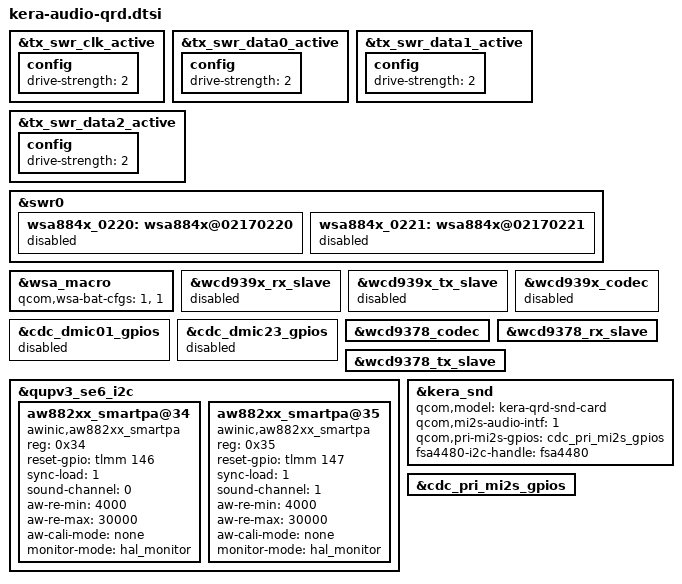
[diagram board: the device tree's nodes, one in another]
// SPDX-License-Identifier: BSD-3-Clause
/*
 * Copyright (c) 2023-2025 Qualcomm Innovation Center, Inc. All rights reserved.
 */
#include "kera-audio-overlay.dtsi"
#include "../kera-audio-lpass-reg.dtsi"

&tx_swr_clk_active {
	config {
		drive-strength = <2>;
	};
};

&tx_swr_data0_active {
	config {
		drive-strength = <2>;
	};
};

&tx_swr_data1_active {
	config {
		drive-strength = <2>;
	};
};

&tx_swr_data2_active {
	config {
		drive-strength = <2>;
	};
};

&swr0 {
	wsa884x_0220: wsa884x@02170220 {
		status = "disabled";
	};

	wsa884x_0221: wsa884x@02170221 {
		status = "disabled";
	};
};

&wsa_macro {
	qcom,wsa-bat-cfgs = <1>, <1>;
};

&wcd939x_rx_slave {
	status = "disabled";
};

&wcd939x_tx_slave {
	status = "disabled";
};

&wcd939x_codec {
	status = "disabled";
};

&cdc_dmic01_gpios {
	status = "disabled";
};

&cdc_dmic23_gpios {
	status = "disabled";
};

&wcd9378_codec {
	status = "okay";
};

&wcd9378_rx_slave {
	status = "okay";
};

&wcd9378_tx_slave {
	status = "okay";
};

&qupv3_se6_i2c {
	status = "ok";
	/* AWINIC AW882XX Smart PA */
	aw882xx_smartpa@34 {
		compatible = "awinic,aw882xx_smartpa";
		reg = <0x34>;
		reset-gpio = <&tlmm 146 0>; /*aw88230,aw88261,aw88265,aw88257,aw88082不能配置*/
		//irq-gpio = <&tlmm 136 0x2008>;
		sync-load = <1>;
		sound-channel = <0>; /*0:pri_l 1:pri_r 2:sec_l 3:sec_r*/
		aw-re-min = <4000>;
		aw-re-max= <30000>;
		aw-cali-mode = "none"; /*带IV的产品无需配置此项*/
		monitor-mode = "hal_monitor";
		status = "okay";
	};
	aw882xx_smartpa@35 {
		compatible = "awinic,aw882xx_smartpa";
		reg = <0x35>;
		reset-gpio = <&tlmm 147 0>; /*aw88230,aw88261,aw88265,aw88257,aw88082不能配置*/
		//irq-gpio = <&tlmm 143 0x2008>;
		sync-load = <1>;
		sound-channel = <1>; /*0:pri_l 1:pri_r 2:sec_l 3:sec_r*/
		aw-re-min = <4000>;
		aw-re-max= <30000>;
		aw-cali-mode = "none"; /*带IV的产品无需配置此项*/
		monitor-mode = "hal_monitor";
		status = "okay";
	};
	/* AWINIC AW882XX Smart PA End */
};

&kera_snd {
	qcom,model = "kera-qrd-snd-card";
	//asoc-codec  = <&stub_codec>, <&lpass_cdc>,
	//		<&wcd9378_codec>, <&wsa884x_0220>;
	//asoc-codec-names = "msm-stub-codec.1", "lpass-cdc",
	//		"wcd9378_codec", "wsa-codec1";
	//qcom,wsa-max-devs = <1>;
	qcom,mi2s-audio-intf = <1>;
	qcom,pri-mi2s-gpios = <&cdc_pri_mi2s_gpios>;
	fsa4480-i2c-handle = <&fsa4480>;
};

&cdc_pri_mi2s_gpios {
	status = "ok";
};
